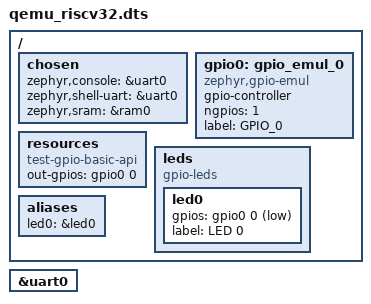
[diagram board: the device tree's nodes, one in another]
/* SPDX-License-Identifier: Apache-2.0 */

/dts-v1/;

#include <qemu/virt-riscv32.dtsi>
#include <zephyr/dt-bindings/gpio/gpio.h> //understand naming bindings like GPIO_ACTIVE_HIGH etc..

/ {
	chosen {
		zephyr,console = &uart0;
		zephyr,shell-uart = &uart0;
		zephyr,sram = &ram0;
	};


	gpio0: gpio_emul_0 {
		compatible = "zephyr,gpio-emul";
		gpio-controller;
		ngpios = <1>; // Number of GPIO pins
		label = "GPIO_0";
		#gpio-cells = <2>;
	
	};

	resources {
		compatible = "test-gpio-basic-api";
		out-gpios = <&gpio0 0 0>; /* Pin 0 */
		//in-gpios = <&gpio0 1 0>; /* Pin 1 */
	};
	
	leds    {
		compatible = "gpio-leds";
		led0: led0 {
			gpios = <&gpio0 0 GPIO_ACTIVE_LOW>; // Connects LED to Pin 0
			label = "LED 0";
		};
	};

	aliases {
		led0 = &led0;
	};

};

&uart0 {
	status = "okay";
};

